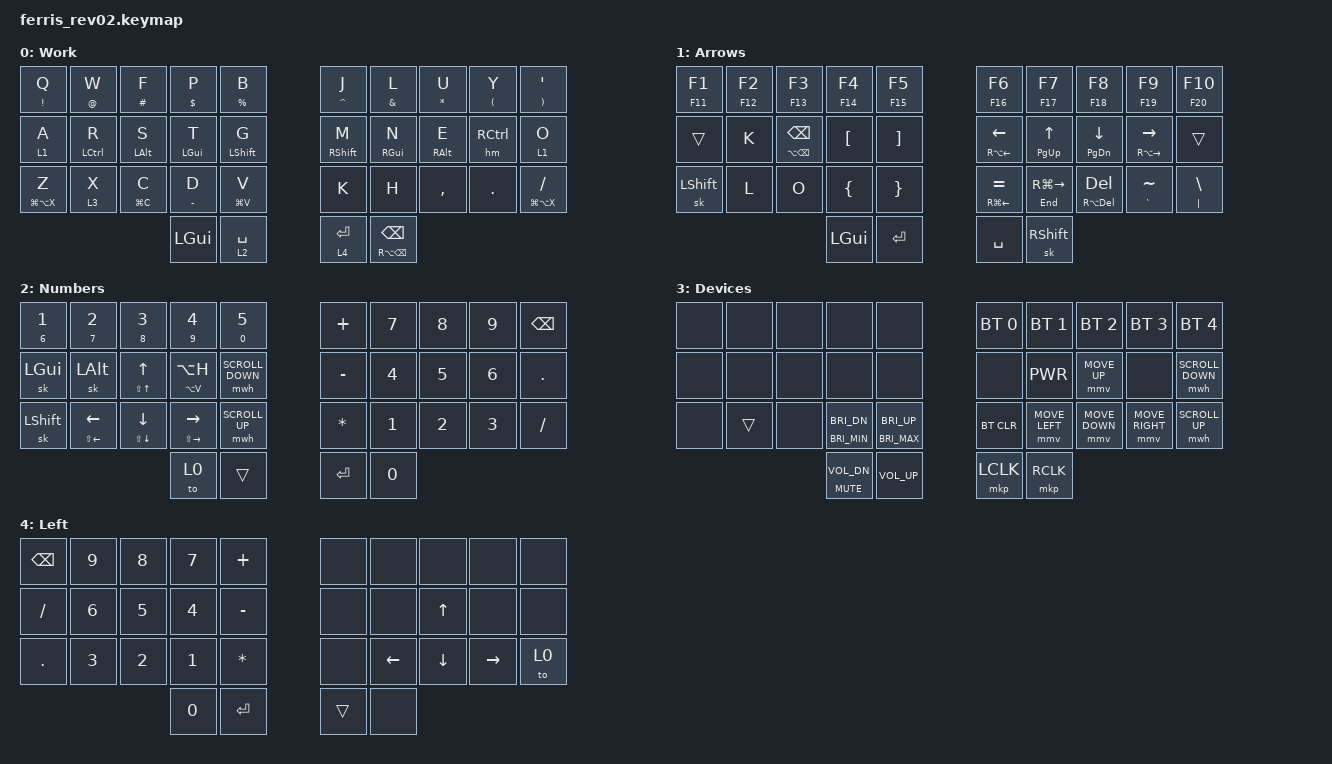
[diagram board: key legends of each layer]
/*
 * Copyright (c) 2020 The ZMK Contributors
 *
 * SPDX-License-Identifier: MIT
 */

#include <behaviors.dtsi>
#include <dt-bindings/zmk/keys.h>
#include <dt-bindings/zmk/bt.h>
#include <dt-bindings/zmk/mouse.h>


#define Work     0
#define Arrows   1
#define Numbers  2
#define Devices  3
#define Left     4



&sk {
    release-after-ms = <3000>;
};

/ { 
 combos {
        compatible = "zmk,combos";
        combo_TILDE {
            timeout-ms = <50>;
            key-positions = <0 1>;
            bindings = <&kp TILDE>;
        };
        combo_CAPS {
            timeout-ms = <50>;
            key-positions = <0 9>;
            bindings = <&kp CAPS>;
        };
        combo_ESC {
            timeout-ms = <50>;
            key-positions = <1 2>;
            bindings = <&kp ESC>;
        };
        combo_LNUM {
            timeout-ms = <50>;
            key-positions = <1 2 3>;
            bindings = <&to 2>;
        };
        combo_NUM_RIGHT_HAND {
            timeout-ms = <50>;
            key-positions = <6 7 8>;
            bindings = <&to 4>;
        };
    combo_MINUS_LEFTHAND {
            timeout-ms = <30>;
            key-positions = <10 13>;
            bindings = <&to 4>;
    };
	combo_BACK {
            timeout-ms = <30>;
            key-positions = <11 13>;
            bindings = <&kp LG(LBKT)>;
        };
    combo_FORWARD {
            timeout-ms = <30>;
            key-positions = <11 12>;
            bindings = <&kp LG(RBKT)>;
        };
    combo_TAB {
            timeout-ms = <30>;
            key-positions = <12 13>;
            bindings = <&kp TAB>;
        };
    combo_base {
            timeout-ms = <30>;
            key-positions = <11 12 13>;
            bindings = <&to 0>;
        };
    combo_mLCLK {
            timeout-ms = <30>;
            key-positions = <12 14>;
            bindings = <&mkp LCLK>;
        };
    combo_mRCLK {
            timeout-ms = <30>;
            key-positions = <13 14>;
            bindings = <&mkp RCLK>;
        };
    combo_COLON {
            timeout-ms = <30>;
            key-positions = <16 17>;
            bindings = <&kp COLON>;
        };
    combo_SEMI {
            timeout-ms = <30>;
            key-positions = <17 18>;
            bindings = <&kp SEMI>;
        };
    combo_MoveToLeftTab {
            timeout-ms = <50>;
            key-positions = <21 22>;
            bindings = <&kp LG(LA(LEFT))>;
        };
    combo_APP {
            timeout-ms = <30>;
            key-positions = <22 23>;
            bindings = <&kp LG(TAB)>;
        };
	combo_WINDOW {
            timeout-ms = <30>;
            key-positions = <21 22 23>;
            bindings = <&kp LG(GRAVE)>;
        };
	combo_MoveToRightTab {
            timeout-ms = <50>;
            key-positions = <23 24>;
            bindings = <&kp LG(LA(RIGHT))>;
        };
	combo_HOME {
            timeout-ms = <50>;
            key-positions = <26 27>;
            bindings = <&kp HOME>;
        };
	combo_END {
            timeout-ms = <50>;
            key-positions = <27 28>;
            bindings = <&kp END>;
        };
    combo_UNDER {
            timeout-ms = <50>;
            key-positions = <21 28>;
            bindings = <&kp UNDER>;
        };
    combo_MINUS {
            timeout-ms = <50>;
            key-positions = <22 27>;
            bindings = <&kp MINUS>;
        };
    combo_SPACE {
            timeout-ms = <50>;
            key-positions = <24 31>;
            bindings = <&kp SPACE>;
        };
    combo_RETURN {
            timeout-ms = <50>;
            key-positions = <23 31>;
            bindings = <&kp RET>;
        };
   };
   behaviors {
         hm: homerow_mods {
            compatible = "zmk,behavior-hold-tap";
            label = "HOMEROW_MODS";
            #binding-cells = <2>;
            tapping-term-ms = <220>;
            quick_tap_ms = <0>;
            flavor = "tap-preferred";
            bindings = <&kp>, <&kp>;
        };
        td: tapdance {
            compatible = "zmk,behavior-hold-tap";
            label = "TAPDANCE";
            #binding-cells = <2>;
            tapping-term-ms = <200>;
            quick_tap_ms = <0>;
            flavor = "tap-preferred";
            bindings = <&kp>, <&kp>;
        };
   };

       keymap {
                compatible = "zmk,keymap";

                Work {
                        bindings = <
       &td EXCL Q       &td AT W     &td HASH F      &td DLLR P            &td PRCNT B         &td CARET J   &td AMPS L    &td STAR U     &td LPAR Y    &td RPAR SQT
       &lt 1 A          &hm LCTRL R  &hm LALT S      &hm LGUI T            &hm LSHFT G         &hm RSHIFT M  &hm RGUI N    &hm RALT E     &hm RCTRL     &lt 1 O
       &td LG(LA(X)) Z  &lt 3 X      &td LG(C) C     &td MINUS D           &td LG(V) V         &kp K         &kp H         &kp COMMA      &kp DOT       &td LG(LA(X)) FSLH
                                                     &kp LGUI              &lt 2 SPACE         &lt 4 RET     &td RA(BSPC) BSPC
                        >;
                };
                Arrows {
                        bindings = <
       &td F11 F1 &td F12 F2  &td F13 F3         &td F14 F4     &td F15 F5         &td F16 F6         &td F17 F7         &td F18 F8       &td F19 F9           &td F20 F10
       &trans     &kp K       &td LA(BSPC) BSPC  &kp LBKT       &kp RBKT           &td RA(LEFT) LEFT  &td PG_UP UP       &td PG_DN DOWN   &td RA(RIGHT) RIGHT  &trans
       &sk LSHFT  &kp L       &kp O              &kp LBRC       &kp RBRC           &td RG(LEFT) EQUAL &td END RG(RIGHT)  &td RA(DEL) DEL  &td GRAVE TILDE      &td PIPE BSLH
                                                 &kp LGUI       &kp RET            &kp SPACE          &sk RSHIFT
                        >;
                };
            
                Numbers {
                        bindings = <
       &td N6 N1  &td N7 N2            &td N8 N3          &td N9 N4             &td N0 N5         &kp PLUS   &kp N7   &kp N8     &kp N9   &kp BSPC
       &sk LGUI   &sk LALT             &td LS(UP) UP      &td LA(V) LA(H)       &mwh SCROLL_DOWN  &kp MINUS  &kp N4   &kp N5     &kp N6   &kp DOT
       &sk LSHFT  &td LS(LEFT) LEFT    &td LS(DOWN) DOWN  &td LS(RIGHT) RIGHT   &mwh SCROLL_UP    &kp STAR   &kp N1   &kp N2     &kp N3   &kp FSLH
                                                          &to 0                 &trans            &kp RET    &kp N0
                        >;
                };

		Devices {
			bindings = <
        &none          &none           &none      &none                     &none                   &bt BT_SEL 0   &bt BT_SEL 1    &bt BT_SEL 2    &bt BT_SEL 3     &bt BT_SEL 4
        &none          &none           &none      &none                     &none                   &none          &kp C_PWR       &mmv MOVE_UP    &none            &mwh SCROLL_DOWN
        &none          &trans          &none      &td C_BRI_MIN C_BRI_DN    &td C_BRI_MAX C_BRI_UP  &bt BT_CLR     &mmv MOVE_LEFT  &mmv MOVE_DOWN  &mmv MOVE_RIGHT  &mwh SCROLL_UP
                                                  &td C_MUTE C_VOL_DN       &kp C_VOL_UP            &mkp LCLK      &mkp RCLK
			>;
		};

        Left {
			bindings = <
        &kp BSPC     &kp N9       &kp N8      &kp N7     &kp PLUS         &none   &none       &none       &none     &none    
        &kp FSLH     &kp N6       &kp N5      &kp N4     &kp MINUS        &none   &none       &kp UP      &none     &none    
        &kp DOT      &kp N3       &kp N2      &kp N1     &kp STAR         &none   &kp LEFT    &kp DOWN    &kp RIGHT &to 0
                                              &kp N0     &kp RET          &trans   &none
			>;
		};
     };
};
